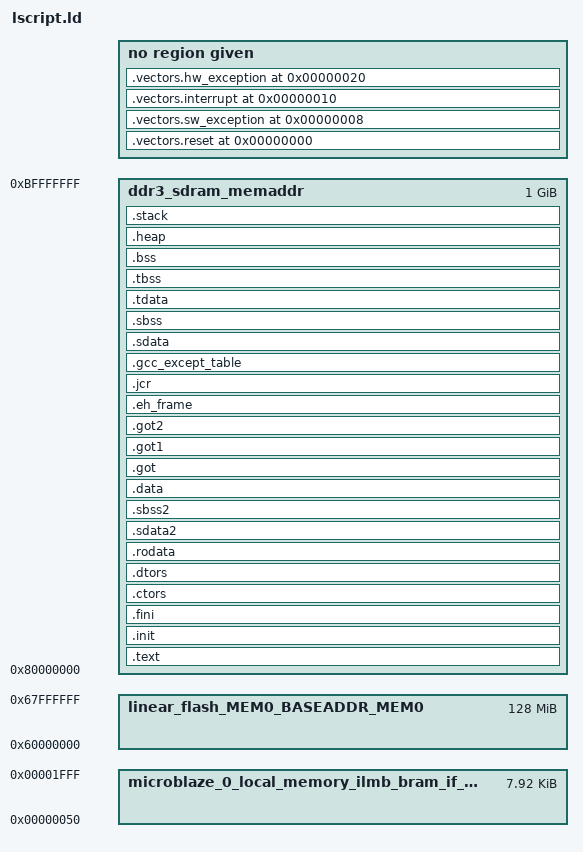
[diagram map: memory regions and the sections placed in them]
/*
 * Copyright (c) 2017 Xilinx, Inc. All rights reserved.
 *
 * Redistribution and use in source and binary forms, with or without
 * modification, are permitted provided that the following conditions are met:
 *
 * 1. Redistributions of source code must retain the above copyright notice,
 *    this list of conditions and the following disclaimer.
 * 2. Redistributions in binary form must reproduce the above copyright notice,
 *    this list of conditions and the following disclaimer in the documentation
 *    and/or other materials provided with the distribution.
 * 3. Neither the name of the <ORGANIZATION> nor the names of its contributors
 *    may be used to endorse or promote products derived from this software
 *    without specific prior written permission.
 *
 * THIS SOFTWARE IS PROVIDED BY THE COPYRIGHT HOLDERS AND CONTRIBUTORS "AS IS"
 * AND ANY EXPRESS OR IMPLIED WARRANTIES, INCLUDING, BUT NOT LIMITED TO, THE
 * IMPLIED WARRANTIES OF MERCHANTABILITY AND FITNESS FOR A PARTICULAR PURPOSE
 * ARE DISCLAIMED. IN NO EVENT SHALL THE COPYRIGHT HOLDER OR CONTRIBUTORS BE
 * LIABLE FOR ANY DIRECT, INDIRECT, INCIDENTAL, SPECIAL, EXEMPLARY, OR
 * CONSEQUENTIAL DAMAGES (INCLUDING, BUT NOT LIMITED TO, PROCUREMENT OF
 * SUBSTITUTE GOODS OR SERVICES; LOSS OF USE, DATA, OR PROFITS; OR BUSINESS
 * INTERRUPTION) HOWEVER CAUSED AND ON ANY THEORY OF LIABILITY, WHETHER IN
 * CONTRACT, STRICT LIABILITY, OR TORT (INCLUDING NEGLIGENCE OR OTHERWISE)
 * ARISING IN ANY WAY OUT OF THE USE OF THIS SOFTWARE, EVEN IF ADVISED OF THE
 * POSSIBILITY OF SUCH DAMAGE.
 */
_STACK_SIZE = DEFINED(_STACK_SIZE) ? _STACK_SIZE : 0x2000;
_HEAP_SIZE = DEFINED(_HEAP_SIZE) ? _HEAP_SIZE : 0x2000;

/* Define Memories in the system */

MEMORY
{
   microblaze_0_local_memory_ilmb_bram_if_cntlr_Mem_microblaze_0_local_memory_dlmb_bram_if_cntlr_Mem : ORIGIN = 0x50, LENGTH = 0x1FB0
   ddr3_sdram_memaddr : ORIGIN = 0x80000000, LENGTH = 0x40000000
   linear_flash_MEM0_BASEADDR_MEM0 : ORIGIN = 0x60000000, LENGTH = 0x8000000
}

/* Specify the default entry point to the program */

ENTRY(_start)

/* Define the sections, and where they are mapped in memory */

SECTIONS
{
.vectors.reset 0x0 : {
   KEEP (*(.vectors.reset))
} 

.vectors.sw_exception 0x8 : {
   KEEP (*(.vectors.sw_exception))
} 

.vectors.interrupt 0x10 : {
   KEEP (*(.vectors.interrupt))
} 

.vectors.hw_exception 0x20 : {
   KEEP (*(.vectors.hw_exception))
} 

.text : {
   *(.text)
   *(.text.*)
   *(.gnu.linkonce.t.*)
} > ddr3_sdram_memaddr

.init : {
   KEEP (*(.init))
} > ddr3_sdram_memaddr

.fini : {
   KEEP (*(.fini))
} > ddr3_sdram_memaddr

.ctors : {
   __CTOR_LIST__ = .;
   ___CTORS_LIST___ = .;
   KEEP (*crtbegin.o(.ctors))
   KEEP (*(EXCLUDE_FILE(*crtend.o) .ctors))
   KEEP (*(SORT(.ctors.*)))
   KEEP (*(.ctors))
   __CTOR_END__ = .;
   ___CTORS_END___ = .;
} > ddr3_sdram_memaddr

.dtors : {
   __DTOR_LIST__ = .;
   ___DTORS_LIST___ = .;
   KEEP (*crtbegin.o(.dtors))
   KEEP (*(EXCLUDE_FILE(*crtend.o) .dtors))
   KEEP (*(SORT(.dtors.*)))
   KEEP (*(.dtors))
   PROVIDE(__DTOR_END__ = .);
   PROVIDE(___DTORS_END___ = .);
} > ddr3_sdram_memaddr

.rodata : {
   __rodata_start = .;
   *(.rodata)
   *(.rodata.*)
   *(.gnu.linkonce.r.*)
   __rodata_end = .;
} > ddr3_sdram_memaddr

.sdata2 : {
   . = ALIGN(8);
   __sdata2_start = .;
   *(.sdata2)
   *(.sdata2.*)
   *(.gnu.linkonce.s2.*)
   . = ALIGN(8);
   __sdata2_end = .;
} > ddr3_sdram_memaddr

.sbss2 : {
   __sbss2_start = .;
   *(.sbss2)
   *(.sbss2.*)
   *(.gnu.linkonce.sb2.*)
   __sbss2_end = .;
} > ddr3_sdram_memaddr

.data : {
   . = ALIGN(4);
   __data_start = .;
   *(.data)
   *(.data.*)
   *(.gnu.linkonce.d.*)
   __data_end = .;
} > ddr3_sdram_memaddr

.got : {
   *(.got)
} > ddr3_sdram_memaddr

.got1 : {
   *(.got1)
} > ddr3_sdram_memaddr

.got2 : {
   *(.got2)
} > ddr3_sdram_memaddr

.eh_frame : {
   *(.eh_frame)
} > ddr3_sdram_memaddr

.jcr : {
   *(.jcr)
} > ddr3_sdram_memaddr

.gcc_except_table : {
   *(.gcc_except_table)
} > ddr3_sdram_memaddr

.sdata : {
   . = ALIGN(8);
   __sdata_start = .;
   *(.sdata)
   *(.sdata.*)
   *(.gnu.linkonce.s.*)
   __sdata_end = .;
} > ddr3_sdram_memaddr

.sbss (NOLOAD) : {
   . = ALIGN(4);
   __sbss_start = .;
   *(.sbss)
   *(.sbss.*)
   *(.gnu.linkonce.sb.*)
   . = ALIGN(8);
   __sbss_end = .;
} > ddr3_sdram_memaddr

.tdata : {
   __tdata_start = .;
   *(.tdata)
   *(.tdata.*)
   *(.gnu.linkonce.td.*)
   __tdata_end = .;
} > ddr3_sdram_memaddr

.tbss : {
   __tbss_start = .;
   *(.tbss)
   *(.tbss.*)
   *(.gnu.linkonce.tb.*)
   __tbss_end = .;
} > ddr3_sdram_memaddr

.bss (NOLOAD) : {
   . = ALIGN(4);
   __bss_start = .;
   *(.bss)
   *(.bss.*)
   *(.gnu.linkonce.b.*)
   *(COMMON)
   . = ALIGN(4);
   __bss_end = .;
} > ddr3_sdram_memaddr

_SDA_BASE_ = __sdata_start + ((__sbss_end - __sdata_start) / 2 );

_SDA2_BASE_ = __sdata2_start + ((__sbss2_end - __sdata2_start) / 2 );

/* Generate Stack and Heap definitions */

.heap (NOLOAD) : {
   . = ALIGN(8);
   _heap = .;
   _heap_start = .;
   . += _HEAP_SIZE;
   _heap_end = .;
} > ddr3_sdram_memaddr

.stack (NOLOAD) : {
   _stack_end = .;
   . += _STACK_SIZE;
   . = ALIGN(8);
   _stack = .;
   __stack = _stack;
} > ddr3_sdram_memaddr

_end = .;
}

